# XMC4500 register map
Vendor: Infineon; File version: 1.5.3 (Reference Manual v1.5)
CPU: CM4 r2p0, little endian, MPU, FPU, 6 interrupt priority bits
Registers are 32-bit, read-write, reset 0x0 unless marked. A register's access mark holds for its fields unless they carry their own. Offsets are from the block's base; [hi:lo] are bit positions.

## CAN_NODE0 — Controller Area Networks
Base 0x48014200
Same registers: CAN_NODE1 0x48014300, CAN_NODE2 0x48014400
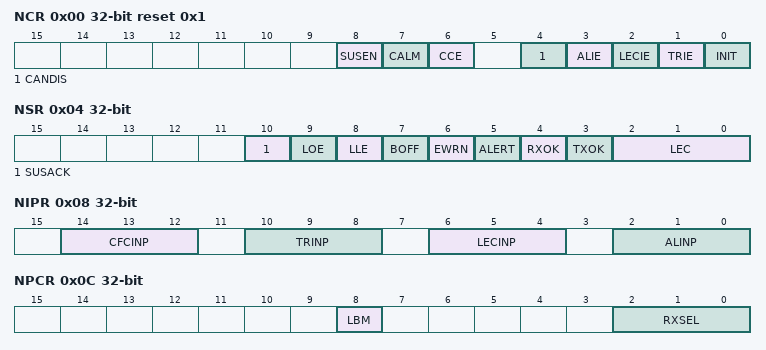
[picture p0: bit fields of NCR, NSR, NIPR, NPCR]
0x00 NCR reset 0x1 — Node Control Register
  [8] SUSEN — Suspend Enable
    0=An OCDS suspend trigger is ignored by the CAN node; 1=An OCDS suspend trigger disables the CAN node: As soon as the CAN node becomes bus-idle or bus-off, bit INIT is internally forced to 1 to disable the CAN node. The actual value of bit INIT remains unchanged.
  [7] CALM — CAN Analyzer Mode
  [6] CCE — Configuration Change Enable
    0=The Bit Timing Register, the Port Control Register, and the Error Counter Register may only be read. All attempts to modify them are ignored.; 1=The Bit Timing Register, the Port Control Register, and the Error Counter Register may be read and written
  [4] CANDIS — CAN Disable
  [3] ALIE — Alert Interrupt Enable
    0=Alert interrupt is disabled; 1=Alert interrupt is enabled
  [2] LECIE — LEC Indicated Error Interrupt Enable
    0=Last error code interrupt is disabled; 1=Last error code interrupt is enabled
  [1] TRIE — Transfer Interrupt Enable
    0=Transfer interrupt is disabled; 1=Transfer interrupt is enabled
  [0] INIT — Node Initialization
    0=Resetting bit INIT enables the participation of the node in the CAN traffic. If the CAN node is in the bus-off state, the ongoing bus-off recovery (which does not depend on the INIT bit) is continued. With the end of the bus-off recovery sequence the CAN node is allowed to take part in the CAN traffic. If the CAN node is not in the bus-off state, a sequence of 11 consecutive recessive bits must be detected before the node is allowed to take part in the CAN traffic.; 1=Setting this bit terminates the participation of this node in the CAN traffic. Any ongoing frame transfer is cancelled and the transmit line goes recessive. If the CAN node is in the bus-off state, then the running bus-off recovery sequence is continued. If the INIT bit is still set after the successful completion of the bus-off recovery sequence, i.e. after detecting 128 sequences of 11 consecutive recessive bits (11 1), then the CAN node leaves the bus-off state but remains inactive as long as INIT remains set.
0x04 NSR access per field — Node Status Register
  [10] SUSACK ro — Suspend Acknowledge
    0=The CAN node is not in Suspend Mode or a suspend request is pending, but the CAN node has not yet reached bus-idle or bus-off; 1=The CAN node is in Suspend Mode: The CAN node is inactive (bit NCR.INIT internally forced to 1) due to an OCDS suspend request
  [9] LOE rw — List Object Error
    0=No List Object Error since last (most recent) flag reset; 1=A List Object Error has been detected during message acceptance filtering. A message object with wrong LIST index entry in the Message Object Control Register has been detected.
  [8] LLE rw — List Length Error
    0=No List Length Error since last (most recent) flag reset; 1=A List Length Error has been detected during message acceptance filtering. The number of elements in the list that belongs to this CAN node differs from the list SIZE given in the list termination pointer.
  [7] BOFF ro — Bus-off Status
    0=CAN controller is not in the bus-off state; 1=CAN controller is in the bus-off state
  [6] EWRN ro — Error Warning Status
    0=No warning limit exceeded; 1=One of the error counters REC or TEC reached the warning limit EWRNLVL
  [5] ALERT rw — Alert Warning
  [4] RXOK rw — Message Received Successfully
    0=No successful reception since last (most recent) flag reset; 1=A message has been received successfully
  [3] TXOK rw — Message Transmitted Successfully
    0=No successful transmission since last (most recent) flag reset; 1=A message has been transmitted successfully (error-free and acknowledged by at least another node)
  [2:0] LEC rw — Last Error Code
0x08 NIPR — Node Interrupt Pointer Register
  [all] fields
    0=Interrupt output line INT_O0 is selected; 1=Interrupt output line INT_O1 is selected; 7=Interrupt output line INT_O7 is selected
  [14:12] CFCINP — Frame Counter Interrupt Node Pointer
  [10:8] TRINP — Transfer OK Interrupt Node Pointer
  [6:4] LECINP — Last Error Code Interrupt Node Pointer
  [2:0] ALINP — Alert Interrupt Node Pointer
0x0C NPCR — Node Port Control Register
  [8] LBM — Loop-Back Mode
    0=Loop-Back Mode is disabled; 1=Loop-Back Mode is enabled. This node is connected to an internal (virtual) loop-back CAN bus. All CAN nodes which are in Loop-Back Mode are connected to this virtual CAN bus so that they can communicate with each other internally. The external transmit line is forced recessive in Loop-Back Mode.
  [2:0] RXSEL — Receive Select
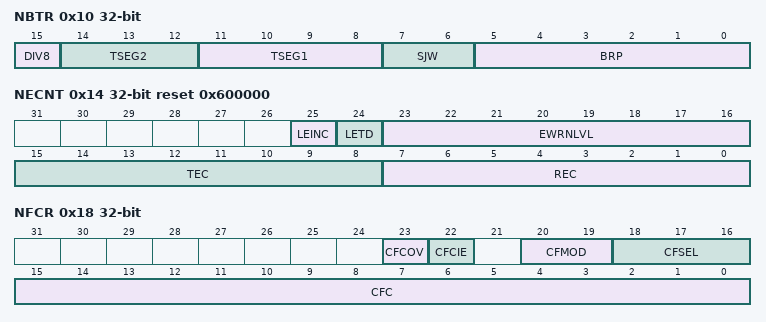
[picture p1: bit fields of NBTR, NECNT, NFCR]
0x10 NBTR — Node Bit Timing Register
  [15] DIV8 — Divide Prescaler Clock by 8
    0=A time quantum lasts (BRP+1) clock cycles; 1=A time quantum lasts 8 (BRP+1) clock cycles
  [14:12] TSEG2 — Time Segment After Sample Point
  [11:8] TSEG1 — Time Segment Before Sample Point
  [7:6] SJW — (Re) Synchronization Jump Width
  [5:0] BRP — Baud Rate Prescaler
0x14 NECNT access per field reset 0x600000 — Node Error Counter Register
  [25] LEINC ro — Last Error Increment
    0=The last error led to an error counter increment of 1; 1=The last error led to an error counter increment of 8
  [24] LETD ro — Last Error Transfer Direction
    0=The last error occurred while the CAN node x was receiver (REC has been incremented); 1=The last error occurred while the CAN node x was transmitter (TEC has been incremented)
  [23:16] EWRNLVL rw — Error Warning Level
  [15:8] TEC rw — Transmit Error Counter
  [7:0] REC rw — Receive Error Counter
0x18 NFCR — Node Frame Counter Register
  [23] CFCOV — CAN Frame Counter Overflow Flag
    0=No overflow has occurred since last flag reset; 1=An overflow has occurred since last flag reset
  [22] CFCIE — CAN Frame Count Interrupt Enable
    0=CAN frame counter overflow interrupt is disabled; 1=CAN frame counter overflow interrupt is enabled
  [20:19] CFMOD — CAN Frame Counter Mode
    0=Frame Count Mode: The frame counter is incremented upon the reception and transmission of frames; 1=Time Stamp Mode: The frame counter is used to count bit times; 2=Bit Timing Mode: The frame counter is used for analysis of the bit timing
  [18:16] CFSEL — CAN Frame Count Selection
    0=The frame counter is incremented (internally) at the beginning of a new bit time. The value is sampled during the SOF bit of a new frame. The sampled value is visible in the CFC field.
  [15:0] CFC — CAN Frame Counter
